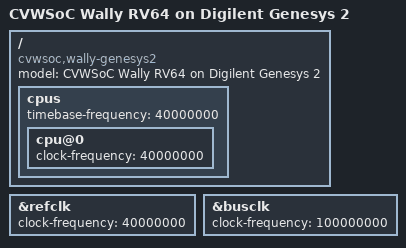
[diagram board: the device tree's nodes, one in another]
/dts-v1/;

 /include/ "cvwsoc-cpu-wally.dtsi"
 /include/ "cvwsoc.dtsi"
 /include/ "cvwsoc-board-genesys2.dtsi"

/ {
  model = "CVWSoC Wally RV64 on Digilent Genesys 2";
  compatible = "cvwsoc,wally-genesys2", "cvwsoc,cvwsoc";

  cpus {
    timebase-frequency = <40000000>;
    cpu@0 {
      clock-frequency = <40000000>;
    };
  };


};

&refclk { clock-frequency = <40000000>; };
&busclk { clock-frequency = <100000000>; };


